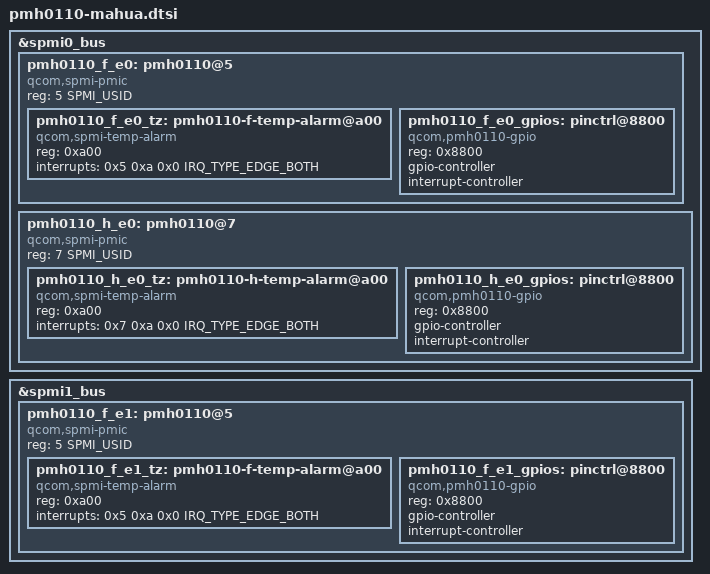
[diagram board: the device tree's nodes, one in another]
// SPDX-License-Identifier: BSD-3-Clause
/*
 * Copyright (c) Qualcomm Technologies, Inc. and/or its subsidiaries.
 */

#include <dt-bindings/interrupt-controller/irq.h>
#include <dt-bindings/spmi/spmi.h>

&spmi0_bus {
	pmh0110_f_e0: pmh0110@5 {
		compatible = "qcom,spmi-pmic";
		reg = <5 SPMI_USID>;
		#address-cells = <1>;
		#size-cells = <0>;

		pmh0110_f_e0_tz: pmh0110-f-temp-alarm@a00 {
			compatible = "qcom,spmi-temp-alarm";
			reg = <0xa00>;
			interrupts = <0x5 0xa 0x0 IRQ_TYPE_EDGE_BOTH>;
			#thermal-sensor-cells = <0>;
		};

		pmh0110_f_e0_gpios: pinctrl@8800 {
			compatible = "qcom,pmh0110-gpio";
			reg = <0x8800>;
			gpio-controller;
			#gpio-cells = <2>;
			interrupt-controller;
			#interrupt-cells = <2>;
		};
	};

	pmh0110_h_e0: pmh0110@7 {
		compatible = "qcom,spmi-pmic";
		reg = <7 SPMI_USID>;
		#address-cells = <1>;
		#size-cells = <0>;

		pmh0110_h_e0_tz: pmh0110-h-temp-alarm@a00 {
			compatible = "qcom,spmi-temp-alarm";
			reg = <0xa00>;
			interrupts = <0x7 0xa 0x0 IRQ_TYPE_EDGE_BOTH>;
			#thermal-sensor-cells = <0>;
		};

		pmh0110_h_e0_gpios: pinctrl@8800 {
			compatible = "qcom,pmh0110-gpio";
			reg = <0x8800>;
			gpio-controller;
			#gpio-cells = <2>;
			interrupt-controller;
			#interrupt-cells = <2>;
		};
	};
};

&spmi1_bus {
	pmh0110_f_e1: pmh0110@5 {
		compatible = "qcom,spmi-pmic";
		reg = <5 SPMI_USID>;
		#address-cells = <1>;
		#size-cells = <0>;

		pmh0110_f_e1_tz: pmh0110-f-temp-alarm@a00 {
			compatible = "qcom,spmi-temp-alarm";
			reg = <0xa00>;
			interrupts = <0x5 0xa 0x0 IRQ_TYPE_EDGE_BOTH>;
			#thermal-sensor-cells = <0>;
		};

		pmh0110_f_e1_gpios: pinctrl@8800 {
			compatible = "qcom,pmh0110-gpio";
			reg = <0x8800>;
			gpio-controller;
			#gpio-cells = <2>;
			interrupt-controller;
			#interrupt-cells = <2>;
		};
	};
};
